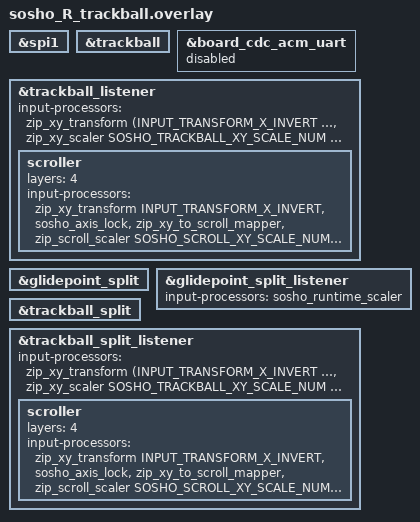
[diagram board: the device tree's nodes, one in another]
#include "sosho_R.dtsi"

/*
 * Daily variant: RIGHT is the central trackball side.
 * SOSHO_TRACKBALL_XY_SCALE_* is a build-time rational scale for both axes.
 * The input processors are source-verified ZMK pointing processors.
 */
&spi1 { status = "okay"; };
&trackball { status = "okay"; };

/* The XIAO board definition also creates a console CDC-ACM port. Keep only
 * the Studio RPC CDC-ACM endpoint on the central so Web Serial cannot select
 * a silent console port by mistake. */
&board_cdc_acm_uart { status = "disabled"; };

&trackball_listener {
    status = "okay";
    /* Correct the sensor orientation on both axes, then apply the 3/4 scale. */
    input-processors = <&zip_xy_transform (INPUT_TRANSFORM_X_INVERT | INPUT_TRANSFORM_Y_INVERT)>,
                       <&zip_xy_scaler SOSHO_TRACKBALL_XY_SCALE_NUM SOSHO_TRACKBALL_XY_SCALE_DEN>;

    /* Layer 4 is the reserved ZMK Studio scroll layer.  MO(4) keeps it
     * active only while the assigned key is held. */
    scroller {
        layers = <4>;
        /* Keep horizontal orientation, reverse vertical scroll direction, and
         * apply the configured 35% scroll amount. */
        input-processors = <&zip_xy_transform INPUT_TRANSFORM_X_INVERT>,
                           <&sosho_axis_lock>,
                           <&zip_xy_to_scroll_mapper>,
                           /* Scale the final wheel events, rather than the
                            * pre-mapped sensor deltas, so the scroll gain is
                            * unambiguous on the host HID report. */
                           <&zip_scroll_scaler SOSHO_SCROLL_XY_SCALE_NUM SOSHO_SCROLL_XY_SCALE_DEN>;
    };
};

/* The central receives the left peripheral's trackpad input here. */
&glidepoint_split { status = "okay"; };
&glidepoint_split_listener {
    status = "okay";
    /* The left peripheral uses the official relative path. Keep raw
     * BTN_TOUCH events so the normal ZMK pointing listener can generate a
     * reliable primary click. Right-click/edge-scroll gesture processors
     * are intentionally not part of the release profile. */
    input-processors = <&sosho_runtime_scaler>;
};

/* Keep the alternate left-trackball combination available. */
&trackball_split { status = "okay"; };
&trackball_split_listener {
    status = "okay";
    input-processors = <&zip_xy_transform (INPUT_TRANSFORM_X_INVERT | INPUT_TRANSFORM_Y_INVERT)>,
                       <&zip_xy_scaler SOSHO_TRACKBALL_XY_SCALE_NUM SOSHO_TRACKBALL_XY_SCALE_DEN>;

    scroller {
        layers = <4>;
        input-processors = <&zip_xy_transform INPUT_TRANSFORM_X_INVERT>,
                           <&sosho_axis_lock>,
                           <&zip_xy_to_scroll_mapper>,
                           <&zip_scroll_scaler SOSHO_SCROLL_XY_SCALE_NUM SOSHO_SCROLL_XY_SCALE_DEN>;
    };
};
